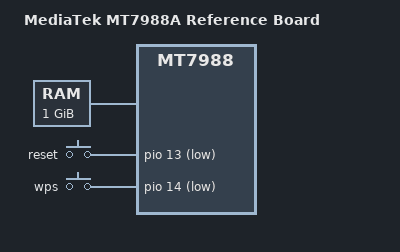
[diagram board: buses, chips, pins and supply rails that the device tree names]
// SPDX-License-Identifier: (GPL-2.0 OR MIT)
/*
 * Copyright (C) 2024 MediaTek Inc.
 * Author: Sam.Shih <sam.shih@mediatek.com>
 */

/dts-v1/;
#include "mt7988a-rfb.dts"

/ {
	model = "MediaTek MT7988A Reference Board";
	compatible = "mediatek,mt7988d-rfb",
		     "mediatek,mt7988d",
		     "mediatek,mt7988";

	chosen {
		bootargs = "console=ttyS0,115200n1 loglevel=6  \
			    earlycon=uart8250,mmio32,0x11000000 \
			    pci=pcie_bus_perf ubi.block=0,firmware root=/dev/fit0 \
			    rootwait";
	};

	cpus {
		/delete-node/ cpu@3;
	};

	memory {
		reg = <0 0x40000000 0 0x40000000>;
	};

	gpio-keys {
		compatible = "gpio-keys";

		reset {
			label = "reset";
			linux,code = <KEY_RESTART>;
			gpios = <&pio 13 GPIO_ACTIVE_LOW>;
		};

		wps {
			label = "wps";
			linux,code = <KEY_WPS_BUTTON>;
			gpios = <&pio 14 GPIO_ACTIVE_LOW>;
		};
	};
};

/*
 * MT7988A have 4 pcies:
 * -pcie0: pcie@11300000 - Gen3 2 lanes
 * -pcie1: pcie@11310000 - Gen3 2 lanes
 * -pcie2: pcie@11280000 - Gen3 1 lane (shared with u3 port of ssusb0)
 * -pcie3: pcie@11290000 - Gen3 1 lane
 * and 2 usb controllers
 * -ssusb0: usb@11190000 (u2 port and u3 port, u3 port shared with pcie2)
 * -ssusb1: usb@11200000 (u2 port and u3 port)
 *
 * MT7988D only support 2 pcies:
 * -pcie0: pcie@11300000 - Gen3 2 lanes
 * -pcie3: pcie@11290000 - Gen3 1 lane
 * and 1 usb controller
 * -ssusb1: usb@11200000 (u2 port and u3 port)
 */

&pcie1 {
	status = "disabled";
};

&pcie2 {
	status = "disabled";
};

&ssusb0 {
	status = "disabled";
};

&xphy {
	status = "disabled";
};

